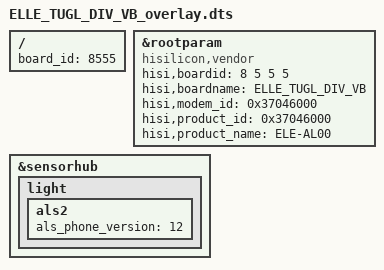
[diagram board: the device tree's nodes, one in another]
/**
 * Copyright (C) 2014 Hisilicon Ltd.
 *
 *  This program is free software; you can redistribute it and/or modify
 *  it under the terms of the GNU General Public License version 2 as
 *  publishhed by the Free Software Foundation.
 */

/dts-v1/;
/plugin/;
/include/ "ELLE_TUGL_DIV_VA_overlay.dtsi"
/include/ "ELLE_TUGL_DIV_VB_pin.dtsi"
/include/ "ELLE_TUGL_DIV_VB_modem_pin.dtsi"

/ {
    board_id = <8555>;
};
    &rootparam{
		compatible = "hisilicon,vendor";
		hisi,boardid = <8 5 5 5>;
		hisi,boardname = "ELLE_TUGL_DIV_VB";
		hisi,modem_id = <0x37046000>;
		hisi,product_id = <0x37046000>;
		hisi,product_name = "ELE-AL00";
	};
	&sensorhub{
		light{
			als2{
				als_phone_version = <12>;
			};
		};
	};
